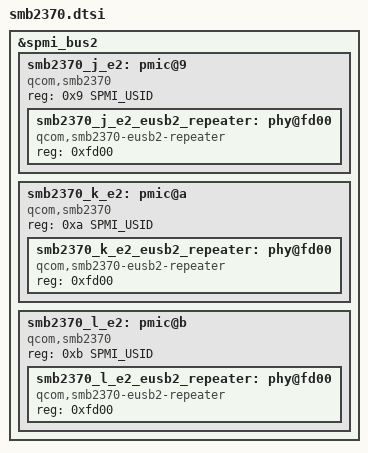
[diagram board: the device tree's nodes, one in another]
// SPDX-License-Identifier: GPL-2.0-only
/*
 * Copyright (c) Qualcomm Technologies, Inc. and/or its subsidiaries.
 */

&spmi_bus2 {
	smb2370_j_e2: pmic@9 {
		compatible = "qcom,smb2370", "qcom,spmi-pmic";
		reg = <0x9 SPMI_USID>;
		#address-cells = <1>;
		#size-cells = <0>;

		smb2370_j_e2_eusb2_repeater: phy@fd00 {
			compatible = "qcom,smb2370-eusb2-repeater";
			reg = <0xfd00>;
			#phy-cells = <0>;
		};
	};

	smb2370_k_e2: pmic@a {
		compatible = "qcom,smb2370", "qcom,spmi-pmic";
		reg = <0xa SPMI_USID>;
		#address-cells = <1>;
		#size-cells = <0>;

		smb2370_k_e2_eusb2_repeater: phy@fd00 {
			compatible = "qcom,smb2370-eusb2-repeater";
			reg = <0xfd00>;
			#phy-cells = <0>;
		};
	};

	smb2370_l_e2: pmic@b {
		compatible = "qcom,smb2370", "qcom,spmi-pmic";
		reg = <0xb SPMI_USID>;
		#address-cells = <1>;
		#size-cells = <0>;

		smb2370_l_e2_eusb2_repeater: phy@fd00 {
			compatible = "qcom,smb2370-eusb2-repeater";
			reg = <0xfd00>;
			#phy-cells = <0>;
		};
	};
};
